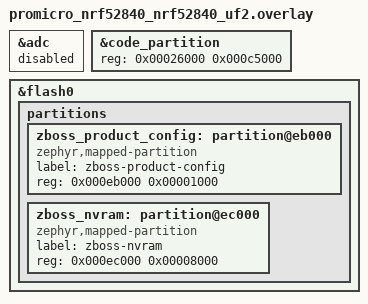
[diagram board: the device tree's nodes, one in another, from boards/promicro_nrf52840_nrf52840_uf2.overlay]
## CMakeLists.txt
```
cmake_minimum_required(VERSION 3.20.0)
set(ZEPHYR_EXTRA_MODULES "C:/ncs/ncs-zigbee")
find_package(Zephyr REQUIRED HINTS $ENV{ZEPHYR_BASE})
project(zigbutton_diag_d2)
target_sources(app PRIVATE src/main.c src/d2_monitor.c)
get_property(diag_libs GLOBAL PROPERTY ZEPHYR_LIBS)
set(diag_replaced 0)
foreach(diag_lib IN LISTS diag_libs)
  get_target_property(diag_sources ${diag_lib} SOURCES)
  if(diag_sources)
    set(diag_new_sources "")
    foreach(diag_source IN LISTS diag_sources)
      if(diag_source MATCHES "(^|/)zb_nrf_platform[.]c$")
        list(APPEND diag_new_sources "${CMAKE_CURRENT_SOURCE_DIR}/src/zb_nrf_platform_d2.c")
        math(EXPR diag_replaced "${diag_replaced} + 1")
      else()
        list(APPEND diag_new_sources "${diag_source}")
      endif()
    endforeach()
    set_property(TARGET ${diag_lib} PROPERTY SOURCES "${diag_new_sources}")
  endif()
endforeach()
if(NOT diag_replaced EQUAL 1)
  message(FATAL_ERROR "D2 must replace exactly one OSIF platform source; found ${diag_replaced}")
endif()
```

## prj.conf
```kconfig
CONFIG_GPIO=y
CONFIG_ADC=n
CONFIG_HEAP_MEM_POOL_SIZE=2048
CONFIG_SYSTEM_WORKQUEUE_STACK_SIZE=2048
CONFIG_RAM_POWER_DOWN_LIBRARY=y
CONFIG_PM_DEVICE=n
CONFIG_WATCHDOG=n
CONFIG_SERIAL=n
CONFIG_CONSOLE=n
CONFIG_UART_CONSOLE=n
CONFIG_LOG=n
CONFIG_SHELL=n
CONFIG_USB_DEVICE_STACK=n
CONFIG_USB_DEVICE_STACK_NEXT=n
CONFIG_DK_LIBRARY=n
CONFIG_DIAG_ZIGBEE=y
CONFIG_ZIGBEE_ADD_ON=y
CONFIG_ZIGBEE_APP_UTILS=y
CONFIG_ZIGBEE_ROLE_END_DEVICE=y
CONFIG_ZIGBEE_CHANNEL_SELECTION_MODE_SINGLE=y
CONFIG_ZIGBEE_CHANNEL=11
```

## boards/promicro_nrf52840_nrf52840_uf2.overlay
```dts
/* Exact original partition map; ADC disabled for BOTH diagnostics. */
&adc { status = "disabled"; };

&code_partition {
    reg = <0x00026000 0x000c5000>;
};


/delete-node/ &storage_partition;


&flash0 {
    partitions {

        zboss_product_config: partition@eb000 {
            compatible = "zephyr,mapped-partition";
            label = "zboss-product-config";
            reg = <0x000eb000 0x00001000>;
        };

        zboss_nvram: partition@ec000 {
            compatible = "zephyr,mapped-partition";
            label = "zboss-nvram";
            reg = <0x000ec000 0x00008000>;
        };
    };
};
```

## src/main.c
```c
#include <zephyr/kernel.h>
#include <zephyr/drivers/gpio.h>
#include <zephyr/sys/atomic.h>
#include <ram_pwrdn.h>
#include "d2_monitor.h"

#define BUTTON_PIN 17
#define DEBOUNCE_MS 35
#define LED_MS 20
static const struct device *gpio0 = DEVICE_DT_GET(DT_NODELABEL(gpio0));
static const struct gpio_dt_spec led = GPIO_DT_SPEC_GET(DT_ALIAS(led0), gpios);
static struct gpio_callback button_cb;
static struct k_work_delayable debounce_work, led_off_work;
static int last_state;
static struct k_work_delayable status_work;
static atomic_t status_request;
static unsigned int status_edges;
static bool status_on;
static void status_handler(struct k_work *work)
{
    ARG_UNUSED(work);
    unsigned int request = atomic_set(&status_request, 0);
    if (request) { status_edges = request * 2; status_on = false; }
    if (!status_edges) { return; }
    status_on = !status_on;
    if (gpio_pin_set_dt(&led, status_on) != 0) { return; }
    status_edges--;
    if (status_edges) {
        k_work_reschedule(&status_work, status_on ? K_MSEC(150) : K_MSEC(350));
    }
}
static void show_status(unsigned int count)
{
    atomic_set(&status_request, count);
    k_work_reschedule(&status_work, K_MSEC(700));
}

/* RAM-only diagnostics; no periodic work, logging or flash writes. */
volatile int diag_init_error;
atomic_t diag_irq_count, diag_gpio_errors, diag_scheduler_errors;

#if defined(CONFIG_DIAG_ZIGBEE)
/* Cluster support is supplied by this add-on libzboss configuration. */
#include <zboss_api.h>
#include <zboss_api_addons.h>
#include <zboss_api_zcl.h>
/* On/Off diagnostic endpoint, device version 0. */
#include <zigbee/zigbee_app_utils.h>
#include <zb_nrf_platform.h>
static zb_zcl_basic_attrs_t basic;
static zb_zcl_identify_attrs_t identify;
volatile uint32_t diag_buffer_errors, diag_not_joined, diag_sleep_signals;
volatile zb_bool_t diag_rx_on_when_idle;
volatile zb_ret_t diag_last_signal_status, diag_last_buffer_result;
ZB_ZCL_DECLARE_BASIC_SERVER_ATTRIB_LIST(basic_attrs, &basic.zcl_version, &basic.power_source);
ZB_ZCL_DECLARE_IDENTIFY_SERVER_ATTRIB_LIST(identify_attrs, &identify.identify_time);
static zb_zcl_cluster_desc_t clusters[] = {
    ZB_ZCL_CLUSTER_DESC(ZB_ZCL_CLUSTER_ID_BASIC, ZB_ZCL_ARRAY_SIZE(basic_attrs, zb_zcl_attr_t), basic_attrs, ZB_ZCL_CLUSTER_SERVER_ROLE, ZB_ZCL_MANUF_CODE_INVALID),
    ZB_ZCL_CLUSTER_DESC(ZB_ZCL_CLUSTER_ID_IDENTIFY, ZB_ZCL_ARRAY_SIZE(identify_attrs, zb_zcl_attr_t), identify_attrs, ZB_ZCL_CLUSTER_SERVER_ROLE, ZB_ZCL_MANUF_CODE_INVALID),
    ZB_ZCL_CLUSTER_DESC(ZB_ZCL_CLUSTER_ID_ON_OFF, 0, NULL, ZB_ZCL_CLUSTER_CLIENT_ROLE, ZB_ZCL_MANUF_CODE_INVALID),
};
ZB_DECLARE_SIMPLE_DESC(2, 1);
ZB_AF_SIMPLE_DESC_TYPE(2, 1) simple_desc = {
    1, ZB_AF_HA_PROFILE_ID, ZB_HA_ON_OFF_SWITCH_DEVICE_ID,
    0, 0, 2, 1,
    { ZB_ZCL_CLUSTER_ID_BASIC, ZB_ZCL_CLUSTER_ID_IDENTIFY, ZB_ZCL_CLUSTER_ID_ON_OFF }
};
ZB_AF_DECLARE_ENDPOINT_DESC(ep, 1, ZB_AF_HA_PROFILE_ID, 0, NULL,
    ZB_ZCL_ARRAY_SIZE(clusters, zb_zcl_cluster_desc_t), clusters,
    (zb_af_simple_desc_1_1_t *)&simple_desc, 0, NULL, 0, NULL);
ZBOSS_DECLARE_DEVICE_CTX_1_EP(device_ctx, ep);

static void send_toggle(zb_bufid_t bufid)
{
    if (!ZB_JOINED()) {
        diag_not_joined++;
        zb_buf_free(bufid);
        return;
    }
    zb_uint16_t destination = 0x0000;
    ZB_ZCL_ON_OFF_SEND_REQ(bufid, destination, ZB_APS_ADDR_MODE_16_ENDP_PRESENT,
        1, 1, ZB_AF_HA_PROFILE_ID, ZB_ZCL_DISABLE_DEFAULT_RESPONSE,
        ZB_ZCL_CMD_ON_OFF_TOGGLE_ID, NULL);
}
static void button_zigbee(zb_uint8_t param, zb_uint16_t unused)
{
    ARG_UNUSED(param);
    ARG_UNUSED(unused);
    show_status(d2_classify(ZB_JOINED()));
    user_input_indicate();
    diag_last_buffer_result = zb_buf_get_out_delayed(send_toggle);
    if (diag_last_buffer_result != RET_OK) {
        diag_buffer_errors++;
    }
}
void zboss_signal_handler(zb_bufid_t bufid)
{
    zb_zdo_app_signal_type_t signal = zb_get_app_signal(bufid, NULL);
    diag_rx_on_when_idle = zb_get_rx_on_when_idle();
    if (signal == ZB_COMMON_SIGNAL_CAN_SLEEP) {
        diag_sleep_signals++;
    }
    diag_last_signal_status = zigbee_default_signal_handler(bufid);
    if (bufid) {
        zb_buf_free(bufid);
    }
}
#endif

static void led_off(struct k_work *work)
{
    ARG_UNUSED(work);
    if (gpio_pin_set_dt(&led, 0) != 0) {
        atomic_inc(&diag_gpio_errors);
    }
}
static void debounce(struct k_work *work)
{
    ARG_UNUSED(work);
    int state = gpio_pin_get(gpio0, BUTTON_PIN);
    if (state < 0) {
        atomic_inc(&diag_gpio_errors);
        return;
    }
    if (state == last_state) {
        return;
    }
    last_state = state;
#if defined(CONFIG_DIAG_ZIGBEE)
    if (ZB_SCHEDULE_APP_CALLBACK2(button_zigbee, 0, 0) != RET_OK) {
        atomic_inc(&diag_scheduler_errors);
    }
#endif
}
static void button_irq(const struct device *dev, struct gpio_callback *cb, uint32_t pins)
{
    ARG_UNUSED(dev);
    ARG_UNUSED(cb);
    ARG_UNUSED(pins);
    atomic_inc(&diag_irq_count);
    if (gpio_pin_set_dt(&led, 1) != 0) {
        atomic_inc(&diag_gpio_errors);
    }
    if (k_work_reschedule(&led_off_work, K_MSEC(LED_MS)) < 0) {
        atomic_inc(&diag_scheduler_errors);
    }
    if (k_work_reschedule(&debounce_work, K_MSEC(DEBOUNCE_MS)) < 0) {
        atomic_inc(&diag_scheduler_errors);
    }
}
static int gpio_init(void)
{
    if (!device_is_ready(gpio0) || !gpio_is_ready_dt(&led)) {
        return -ENODEV;
    }
    int err = gpio_pin_configure_dt(&led, GPIO_OUTPUT_INACTIVE);
    if (err) { return err; }
    err = gpio_pin_configure(gpio0, BUTTON_PIN, GPIO_INPUT | GPIO_PULL_UP);
    if (err) { return err; }
    last_state = gpio_pin_get(gpio0, BUTTON_PIN);
    if (last_state < 0) { return last_state; }
    k_work_init_delayable(&led_off_work, led_off);
    k_work_init_delayable(&debounce_work, debounce);
    gpio_init_callback(&button_cb, button_irq, BIT(BUTTON_PIN));
    err = gpio_add_callback(gpio0, &button_cb);
    if (err) { return err; }
    return gpio_pin_interrupt_configure(gpio0, BUTTON_PIN, GPIO_INT_EDGE_BOTH);
}
int main(void)
{
    k_work_init_delayable(&status_work, status_handler);
    d2_monitor_init();
    diag_init_error = gpio_init();
    if (diag_init_error) { return 0; }
#if defined(CONFIG_DIAG_ZIGBEE)
    basic.zcl_version = ZB_ZCL_VERSION;
    basic.power_source = ZB_ZCL_BASIC_POWER_SOURCE_BATTERY;
    identify.identify_time = ZB_ZCL_IDENTIFY_IDENTIFY_TIME_DEFAULT_VALUE;
    ZB_AF_REGISTER_DEVICE_CTX(&device_ctx);
    zigbee_configure_sleepy_behavior(true);
    diag_rx_on_when_idle = zb_get_rx_on_when_idle();
#endif
    if (IS_ENABLED(CONFIG_RAM_POWER_DOWN_LIBRARY)) { power_down_unused_ram(); }
#if defined(CONFIG_DIAG_ZIGBEE)
    zigbee_enable();
#endif
    /* Block main permanently. Zephyr idle performs architecture CPU sleep. */
    k_sleep(K_FOREVER);
    return 0;
}
```

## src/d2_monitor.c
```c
/* Observation only: same-thread accounting around the original k_poll.
 * Wall time inside k_poll is NOT a measurement of CPU idle or radio-off time.
 * All calls after init run in the ZBOSS thread. No timer and no extra wakeup.
 */
#include <zephyr/kernel.h>
#include "d2_monitor.h"
static int64_t window_start, poll_start;
static uint64_t poll_ticks;
static uint32_t calls;
volatile uint32_t d2_last_poll_percent, d2_last_window_seconds, d2_last_poll_calls;
volatile unsigned int d2_last_code;
void d2_monitor_init(void)
{
    window_start = k_uptime_ticks();
}
void d2_poll_begin(void)
{
    poll_start = k_uptime_ticks();
}
void d2_poll_end(void)
{
    poll_ticks += (uint64_t)(k_uptime_ticks() - poll_start);
    calls++;
}
unsigned int d2_classify(bool joined)
{
    int64_t now = k_uptime_ticks();
    uint64_t elapsed = (uint64_t)(now - window_start);
    d2_last_window_seconds = k_ticks_to_ms_floor64(elapsed) / 1000;
    d2_last_poll_calls = calls;
    d2_last_poll_percent = elapsed ? MIN(100ULL, (poll_ticks * 100ULL) / elapsed) : 0;
    unsigned int code;
    if (!joined) { code = 4; }
    else if (d2_last_window_seconds < 60) { code = 5; }
    else if (d2_last_poll_percent >= 90) { code = 1; }
    else if (d2_last_poll_percent >= 10) { code = 2; }
    else { code = 3; }
    if (d2_last_window_seconds >= 60) {
        window_start = now;
        poll_ticks = 0;
        calls = 0;
    }
    d2_last_code = code;
    return code;
}
```

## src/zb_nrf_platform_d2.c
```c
/*
 * Copyright (c) 2020 Nordic Semiconductor ASA
 *
 * SPDX-License-Identifier: LicenseRef-Nordic-5-Clause
 */

#include <stdlib.h>
#include "d2_monitor.h"
#include <string.h>
#include <zephyr/kernel.h>
#include <zephyr/sys/byteorder.h>
#include <zephyr/sys/reboot.h>
#include <zephyr/logging/log.h>
#include <zephyr/logging/log_ctrl.h>
#include <zephyr/init.h>
#include <ram_pwrdn.h>

#include <hal/nrf_power.h>
#include <hal/nrf_ficr.h>
#if !NRF_POWER_HAS_RESETREAS
#include <hal/nrf_reset.h>
#endif

#ifdef CONFIG_ZIGBEE_SHELL
#include <zigbee/zigbee_shell.h>
#endif
#include <zboss_api.h>
#include "zb_nrf_platform.h"
#include "zb_nrf_crypto.h"

#ifdef CONFIG_ZIGBEE_LIBRARY_NCP_DEV
#include <zb_ncp_nrf_platform.h>
#define SYS_REBOOT_NCP 0x10
#endif /* CONFIG_ZIGBEE_LIBRARY_NCP_DEV */

/* Value that is returned while reading a single byte from the erased flash page .*/
#define FLASH_EMPTY_BYTE 0xFF
/* Broadcast Pan ID value */
#define ZB_BROADCAST_PAN_ID 0xFFFFU
/* The number of bytes to be checked before concluding that the ZBOSS NVRAM is not initialized. */
#define ZB_PAGE_INIT_CHECK_LEN 32

/* EUI64 address configuration */
#if defined(CONFIG_ZIGBEE_UICR_EUI64_ENABLE)
#if defined(CONFIG_SOC_NRF5340_CPUAPP) || defined(CONFIG_SOC_SERIES_NRF54LX)
#define EUI64_ADDR (NRF_UICR->OTP)
#else
#define EUI64_ADDR (NRF_UICR->CUSTOMER)
#endif
#define EUI64_ADDR_HIGH CONFIG_ZIGBEE_UICR_EUI64_REG
#define EUI64_ADDR_LOW  (CONFIG_ZIGBEE_UICR_EUI64_REG + 1)
#else
#define EUI64_ADDR_HIGH 0
#define EUI64_ADDR_LOW  1
#endif /* CONFIG_ZIGBEE_UICR_EUI64_ENABLE */


/**
 * Enumeration representing type of application callback to execute from ZBOSS
 * context.
 */
typedef enum {
	ZB_CALLBACK_TYPE_SINGLE_PARAM,
	ZB_CALLBACK_TYPE_TWO_PARAMS,
	ZB_CALLBACK_TYPE_ALARM_SET,
	ZB_CALLBACK_TYPE_ALARM_CANCEL,
	ZB_GET_OUT_BUF_DELAYED,
	ZB_GET_IN_BUF_DELAYED,
	ZB_GET_OUT_BUF_DELAYED_EXT,
	ZB_GET_IN_BUF_DELAYED_EXT,
} zb_callback_type_t;

/**
 * Type definition of element of the application callback and alarm queue.
 */
typedef struct {
	zb_callback_type_t type;
	zb_callback_t func;
	zb_callback2_t func2;
	zb_uint16_t param;
	zb_uint16_t user_param;
	int64_t alarm_timestamp;
} zb_app_cb_t;


LOG_MODULE_REGISTER(zboss_osif, CONFIG_ZBOSS_OSIF_LOG_LEVEL);

BUILD_ASSERT(CONFIG_ZBOSS_INIT_PRIORITY > CONFIG_ZBOSS_RADIO_INIT_PRIORITY,
	     "ZBOSS init priority must be greater than radio init priority");

/* Signal object to indicate that frame has been received */
static struct k_poll_signal zigbee_sig = K_POLL_SIGNAL_INITIALIZER(zigbee_sig);

/** Global mutex to protect access to the ZBOSS global state.
 *
 * @note Functions for locking/unlocking the mutex are called directly from
 *       ZBOSS core, when the main ZBOSS global variable is accessed.
 */
static K_MUTEX_DEFINE(zigbee_mutex);

/**
 * Message queue, that is used to pass ZBOSS callbacks and alarms from
 * ISR and other threads to ZBOSS main loop context.
 */
K_MSGQ_DEFINE(zb_app_cb_msgq, sizeof(zb_app_cb_t),
	      CONFIG_ZIGBEE_APP_CB_QUEUE_LENGTH, 4);

/**
 * Work queue that will schedule processing of callbacks from the message queue.
 */
static struct k_work zb_app_cb_work;

/**
 * Atomic flag, indicating that the processing callback is still scheduled for
 * execution,
 */
volatile atomic_t zb_app_cb_process_scheduled = ATOMIC_INIT(0);

K_THREAD_STACK_DEFINE(zboss_stack_area, CONFIG_ZBOSS_DEFAULT_THREAD_STACK_SIZE);
static struct k_thread zboss_thread_data;
static k_tid_t zboss_tid;
static bool stack_is_started;

#ifdef CONFIG_ZIGBEE_DEBUG_FUNCTIONS
/**@brief Function for checking if the ZBOSS thread has been created.
 */
bool zigbee_debug_zboss_thread_is_created(void)
{
	if (zboss_tid) {
		return true;
	}
	return false;
}

/**@brief Function for suspending ZBOSS thread.
 */
void zigbee_debug_suspend_zboss_thread(void)
{
	k_thread_suspend(zboss_tid);
}

/**@brief Function for resuming ZBOSS thread.
 */
void zigbee_debug_resume_zboss_thread(void)
{
	k_thread_resume(zboss_tid);
}

/**@brief Function for getting the state of the Zigbee stack thread
 *        processing suspension.
 */
bool zigbee_is_zboss_thread_suspended(void)
{
	if (zboss_tid) {
		if (!(zboss_tid->base.thread_state & _THREAD_SUSPENDED)) {
			return false;
		}
	}
	return true;
}
#endif /* defined(CONFIG_ZIGBEE_DEBUG_FUNCTIONS) */

/**@brief Function for checking if the Zigbee stack has been started.
 *
 * @retval true   Zigbee stack has been started.
 * @retval false  Zigbee stack has not been started yet.
 */
bool zigbee_is_stack_started(void)
{
	return stack_is_started;
}

static void zb_app_cb_process(zb_bufid_t bufid)
{
	zb_ret_t ret_code = RET_OK;
	zb_app_cb_t new_app_cb;

	/* Mark the processing callback as non-scheduled. */
	(void)atomic_set((atomic_t *)&zb_app_cb_process_scheduled, 0);

	/**
	 * From ZBOSS main loop context: process all requests.
	 *
	 * Note: the ZB_SCHEDULE_APP_ALARM is not thread-safe.
	 */
	while (!k_msgq_peek(&zb_app_cb_msgq, &new_app_cb)) {
		switch (new_app_cb.type) {
		case ZB_CALLBACK_TYPE_SINGLE_PARAM:
			ret_code = zb_schedule_app_callback(
					new_app_cb.func,
					(zb_uint8_t)new_app_cb.param);
			break;
		case ZB_CALLBACK_TYPE_TWO_PARAMS:
			ret_code = zb_schedule_app_callback2(
					new_app_cb.func2,
					(zb_uint8_t)new_app_cb.param,
					new_app_cb.user_param);
			break;
		case ZB_CALLBACK_TYPE_ALARM_SET:
		{
			/**
			 * Check if the timeout already passed. If so, use the
			 * lowest value that schedules an alarm, so the user
			 * is still able to cancel the alarm.
			 */
			zb_time_t delay =
				(k_uptime_get() > new_app_cb.alarm_timestamp ?
					1 :
					ZB_MILLISECONDS_TO_BEACON_INTERVAL(
						new_app_cb.alarm_timestamp -
						k_uptime_get())
				);
			ret_code = zb_schedule_app_alarm(
					new_app_cb.func,
					(zb_uint8_t)new_app_cb.param,
					delay);
			break;
		}
		case ZB_CALLBACK_TYPE_ALARM_CANCEL:
			ret_code = zb_schedule_alarm_cancel(
					new_app_cb.func,
					(zb_uint8_t)new_app_cb.param,
					NULL);
			break;
		case ZB_GET_OUT_BUF_DELAYED:
			ret_code = zb_buf_get_out_delayed_func(
				TRACE_CALL(new_app_cb.func));
			break;
		case ZB_GET_IN_BUF_DELAYED:
			ret_code = zb_buf_get_in_delayed_func(
				TRACE_CALL(new_app_cb.func));
			break;
		case ZB_GET_OUT_BUF_DELAYED_EXT:
			ret_code = zb_buf_get_out_delayed_ext_func(
					TRACE_CALL(new_app_cb.func2),
					new_app_cb.user_param,
					new_app_cb.param);
			break;
		case ZB_GET_IN_BUF_DELAYED_EXT:
			ret_code = zb_buf_get_in_delayed_ext_func(
					TRACE_CALL(new_app_cb.func2),
					new_app_cb.user_param,
					new_app_cb.param);
			break;
		default:
			break;
		}

		/* Check for ZBOSS scheduler queue overflow. */
		if (ret_code == RET_OVERFLOW) {
			break;
		}

		/* Flush the element from the message queue. */
		k_msgq_get(&zb_app_cb_msgq, &new_app_cb, K_NO_WAIT);
	}

	/**
	 * In case of overflow error - reschedule the processing callback
	 * to process remaining requests later.
	 */
	if (ret_code == RET_OVERFLOW) {
		k_work_submit(&zb_app_cb_work);
	}
}

static void zb_app_cb_process_schedule(struct k_work *item)
{
	zb_app_cb_t new_app_cb;

	if (k_msgq_peek(&zb_app_cb_msgq, &new_app_cb)) {
		return;
	}

	/* Check if processing callback is already scheduled. */
	if (atomic_set((atomic_t *)&zb_app_cb_process_scheduled, 1) == 1) {
		return;
	}

	/**
	 * From working thread, non-ISR context: schedule processing callback.
	 * Repeat endlessly, because the user was already informed that the
	 * request will be handled.
	 *
	 * Note: the ZB_SCHEDULE_APP_CALLBACK is thread-safe.
	 */
	while (zb_schedule_app_callback(zb_app_cb_process, 0) != RET_OK) {
		k_sleep(K_MSEC(1000));
	}
	zigbee_event_notify(ZIGBEE_EVENT_APP);

	(void)item;
}

int zigbee_init(void)
{
	/* Initialise work queue for processing app callback and alarms. */
	k_work_init(&zb_app_cb_work, zb_app_cb_process_schedule);

#if ZB_TRACE_LEVEL
	/* Set Zigbee stack logging level and traffic dump subsystem. */
	ZB_SET_TRACE_LEVEL(CONFIG_ZBOSS_TRACE_LOG_LEVEL);
	ZB_SET_TRACE_MASK(CONFIG_ZBOSS_TRACE_MASK);
#if CONFIG_ZBOSS_TRAF_DUMP
	ZB_SET_TRAF_DUMP_ON();
#else /* CONFIG_ZBOSS_TRAF_DUMP */
	ZB_SET_TRAF_DUMP_OFF();
#endif /* CONFIG_ZBOSS_TRAF_DUMP */
#endif /* ZB_TRACE_LEVEL */

#ifndef CONFIG_ZB_TEST_MODE_MAC
	/* Initialize Zigbee stack. */
	ZB_INIT("zigbee_thread");

	/* Set device address to the value read from FICR registers. */
	zb_ieee_addr_t ieee_addr;
	zb_osif_get_ieee_eui64(ieee_addr);
	zb_set_long_address(ieee_addr);

	/* Keep or erase NVRAM to save the network parameters
	 * after device reboot or power-off.
	 */
	zb_set_nvram_erase_at_start(ZB_FALSE);

	if (IS_ENABLED(CONFIG_ZIGBEE_TC_REJOIN_ENABLED)) {
		zb_secur_set_tc_rejoin_enabled((zb_bool_t)CONFIG_ZIGBEE_TC_REJOIN_ENABLED);
	}

	/* Don't set zigbee role for NCP device */
#ifndef CONFIG_ZIGBEE_LIBRARY_NCP_DEV

	/* Set channels on which the coordinator will try
	 * to create a new network
	 */
#if defined(CONFIG_ZIGBEE_CHANNEL_SELECTION_MODE_SINGLE)
	zb_uint32_t channel_mask = (1UL << CONFIG_ZIGBEE_CHANNEL);
#elif defined(CONFIG_ZIGBEE_CHANNEL_SELECTION_MODE_MULTI)
	zb_uint32_t channel_mask = CONFIG_ZIGBEE_CHANNEL_MASK;
#else
#error Channel mask undefined!
#endif


#if defined(CONFIG_ZIGBEE_ROLE_COORDINATOR)
	zb_set_network_coordinator_role(channel_mask);
#elif defined(CONFIG_ZIGBEE_ROLE_ROUTER)
	zb_set_network_router_role(channel_mask);

#elif defined(CONFIG_ZIGBEE_ROLE_END_DEVICE)
	zb_set_network_ed_role(channel_mask);
#else
#error Zigbee device role undefined!
#endif

#endif /* CONFIG_ZIGBEE_LIBRARY_NCP_DEV */

#endif /* CONFIG_ZB_TEST_MODE_MAC */

	return 0;
}

SYS_INIT(zigbee_init, POST_KERNEL, CONFIG_ZBOSS_INIT_PRIORITY);

void zigbee_deinit(void)
{
	if (zboss_tid) {
		k_thread_abort(zboss_tid);
		zboss_tid = NULL;
	}

	stack_is_started = false;
	(void)k_work_cancel(&zb_app_cb_work);
	k_msgq_purge(&zb_app_cb_msgq);
	k_poll_signal_reset(&zigbee_sig);
	(void)atomic_clear((atomic_t *)&zb_app_cb_process_scheduled);
}

#if IS_ENABLED(CONFIG_ZIGBEE_LIBRARY_NCP_DEV)
void zb_ncp_app_fw_custom_post_start(void)
{
	stack_is_started = true;
#ifdef CONFIG_ZIGBEE_SHELL
	zb_shell_configure_endpoint();
#endif /* defined(CONFIG_ZIGBEE_SHELL) */
}
#endif

static void zboss_thread(void *arg1, void *arg2, void *arg3)
{
#if !IS_ENABLED(CONFIG_ZIGBEE_LIBRARY_NCP_DEV)
	zb_ret_t zb_err_code;

	zb_err_code = zboss_start_no_autostart();
	__ASSERT(zb_err_code == RET_OK, "Error when starting ZBOSS stack!");

	stack_is_started = true;
#ifdef CONFIG_ZIGBEE_SHELL
	zb_shell_configure_endpoint();
#endif /* defined(CONFIG_ZIGBEE_SHELL) */

	while (1) {
		zboss_main_loop_iteration();
	}

#else /* CONFIG_ZIGBEE_LIBRARY_NCP_DEV */
	/* For NCP mode, the thread implementation (i.e. some initialization part
	 * and main loop) is in the ZBOSS library.
	 */
	zboss_app_main();
#endif
}

zb_bool_t zb_osif_is_inside_isr(void)
{
	return (zb_bool_t)(__get_IPSR() != 0);
}

void zb_osif_enable_all_inter(void)
{
	__ASSERT(zb_osif_is_inside_isr() == 0,
		 "Unable to unlock mutex from interrupt context");
	k_mutex_unlock(&zigbee_mutex);
}

void zb_osif_disable_all_inter(void)
{
	__ASSERT(zb_osif_is_inside_isr() == 0,
		 "Unable to lock mutex from interrupt context");
	k_mutex_lock(&zigbee_mutex, K_FOREVER);
}

zb_ret_t zigbee_schedule_callback(zb_callback_t func, zb_uint8_t param)
{
	if ((zboss_tid) && (k_current_get() == zboss_tid) && (!zb_osif_is_inside_isr())) {
		return zb_schedule_app_callback(func, param);
	}

	zb_app_cb_t new_app_cb = {
		.type = ZB_CALLBACK_TYPE_SINGLE_PARAM,
		.func = func,
		.param = param,
	};

	if (k_msgq_put(&zb_app_cb_msgq, &new_app_cb, K_NO_WAIT)) {
		return RET_OVERFLOW;
	}

	k_work_submit(&zb_app_cb_work);
	return RET_OK;
}

zb_ret_t zigbee_schedule_callback2(zb_callback2_t func,
				   zb_uint8_t param,
				   zb_uint16_t user_param)
{
	if ((zboss_tid) && (k_current_get() == zboss_tid) && (!zb_osif_is_inside_isr())) {
		return zb_schedule_app_callback2(func, param, user_param);
	}

	zb_app_cb_t new_app_cb = {
		.type = ZB_CALLBACK_TYPE_TWO_PARAMS,
		.func2 = func,
		.param = param,
		.user_param = user_param,
	};

	if (k_msgq_put(&zb_app_cb_msgq, &new_app_cb, K_NO_WAIT)) {
		return RET_OVERFLOW;
	}

	k_work_submit(&zb_app_cb_work);
	return RET_OK;
}

zb_ret_t zigbee_schedule_alarm(zb_callback_t func,
			       zb_uint8_t param,
			       zb_time_t run_after)
{
	if ((zboss_tid) && (k_current_get() == zboss_tid) && (!zb_osif_is_inside_isr())) {
		return zb_schedule_app_alarm(func, param, run_after);
	}

	zb_app_cb_t new_app_cb = {
		.type = ZB_CALLBACK_TYPE_ALARM_SET,
		.func = func,
		.param = param,
		.alarm_timestamp = k_uptime_get() +
				   ZB_TIME_BEACON_INTERVAL_TO_MSEC(run_after),
	};

	if (k_msgq_put(&zb_app_cb_msgq, &new_app_cb, K_NO_WAIT)) {
		return RET_OVERFLOW;
	}

	k_work_submit(&zb_app_cb_work);
	return RET_OK;
}

zb_ret_t zigbee_schedule_alarm_cancel(zb_callback_t func, zb_uint8_t param)
{
	if ((zboss_tid) && (k_current_get() == zboss_tid) && (!zb_osif_is_inside_isr())) {
		return zb_schedule_alarm_cancel(func, param, NULL);
	}

	zb_app_cb_t new_app_cb = {
		.type = ZB_CALLBACK_TYPE_ALARM_CANCEL,
		.func = func,
		.param = param,
	};

	if (k_msgq_put(&zb_app_cb_msgq, &new_app_cb, K_NO_WAIT)) {
		return RET_OVERFLOW;
	}

	k_work_submit(&zb_app_cb_work);
	return RET_OK;
}

zb_ret_t zigbee_get_out_buf_delayed(zb_callback_t func)
{
	if ((zboss_tid) && (k_current_get() == zboss_tid) && (!zb_osif_is_inside_isr())) {
		return zb_buf_get_out_delayed_func(func);
	}

	zb_app_cb_t new_app_cb = {
		.type = ZB_GET_OUT_BUF_DELAYED,
		.func = func,
	};

	if (k_msgq_put(&zb_app_cb_msgq, &new_app_cb, K_NO_WAIT)) {
		return RET_OVERFLOW;
	}

	k_work_submit(&zb_app_cb_work);
	return RET_OK;
}

zb_ret_t zigbee_get_in_buf_delayed(zb_callback_t func)
{
	if ((zboss_tid) && (k_current_get() == zboss_tid) && (!zb_osif_is_inside_isr())) {
		return zb_buf_get_in_delayed_func(func);
	}

	zb_app_cb_t new_app_cb = {
		.type = ZB_GET_IN_BUF_DELAYED,
		.func = func,
	};

	if (k_msgq_put(&zb_app_cb_msgq, &new_app_cb, K_NO_WAIT)) {
		return RET_OVERFLOW;
	}

	k_work_submit(&zb_app_cb_work);
	return RET_OK;
}

zb_ret_t zigbee_get_out_buf_delayed_ext(zb_callback2_t func, zb_uint16_t param,
					zb_uint16_t max_size)
{
	if ((zboss_tid) && (k_current_get() == zboss_tid) && (!zb_osif_is_inside_isr())) {
		return zb_buf_get_out_delayed_ext_func(func, param, max_size);
	}

	zb_app_cb_t new_app_cb = {
		.type = ZB_GET_OUT_BUF_DELAYED_EXT,
		.func2 = func,
		.user_param = param,
		.param = max_size,
	};

	if (k_msgq_put(&zb_app_cb_msgq, &new_app_cb, K_NO_WAIT)) {
		return RET_OVERFLOW;
	}

	k_work_submit(&zb_app_cb_work);
	return RET_OK;
}

zb_ret_t zigbee_get_in_buf_delayed_ext(zb_callback2_t func, zb_uint16_t param,
					zb_uint16_t max_size)
{
	if ((zboss_tid) && (k_current_get() == zboss_tid) && (!zb_osif_is_inside_isr())) {
		return zb_buf_get_in_delayed_ext_func(func, param, max_size);
	}

	zb_app_cb_t new_app_cb = {
		.type = ZB_GET_IN_BUF_DELAYED_EXT,
		.func2 = func,
		.user_param = param,
		.param = max_size,
	};

	if (k_msgq_put(&zb_app_cb_msgq, &new_app_cb, K_NO_WAIT)) {
		return RET_OVERFLOW;
	}

	k_work_submit(&zb_app_cb_work);
	return RET_OK;
}

/**@brief SoC general initialization. */
void zb_osif_init(void)
{
	static bool platform_inited;

	if (platform_inited) {
		return;
	}
	platform_inited = true;

#ifdef CONFIG_ZIGBEE_HAVE_SERIAL
	/* Initialise serial trace */
	zb_osif_serial_init();
#endif

	/* Initialise random generator */
	zb_osif_rng_init();

	/* Initialise AES ECB */
	zb_osif_aes_init();

#ifdef ZB_USE_SLEEP
	/* Initialise power consumption routines */
	zb_osif_sleep_init();
#endif /*ZB_USE_SLEEP*/
}

void zb_osif_abort(void)
{
	/* Log ZBOSS error message and flush logs. */
	LOG_ERR("ZBOSS fatal error occurred");
	LOG_PANIC();

#ifdef CONFIG_ZIGBEE_HAVE_SERIAL
	/* Flush ZBOSS trace logs. */
	ZB_OSIF_SERIAL_FLUSH();
#endif

	/* By default reset device or halt if so configured. */
	if (IS_ENABLED(CONFIG_ZBOSS_RESET_ON_ASSERT)) {
		zb_reset(0);
	}
	if (IS_ENABLED(CONFIG_ZBOSS_HALT_ON_ASSERT)) {
		k_fatal_halt(K_ERR_KERNEL_PANIC);
	}
}

uint32_t zigbee_pibcache_pan_id_clear(void)
{
	/* For consistency with zb_nwk_nib_init(), the 0xFFFFU is used,
	 * i.e. ZB_BROADCAST_PAN_ID.
	 */
	ZB_PIBCACHE_PAN_ID() = ZB_BROADCAST_PAN_ID;
	return ZB_BROADCAST_PAN_ID;
}

void zb_reset(zb_uint8_t param)
{
	uint8_t reas = (uint8_t)SYS_REBOOT_COLD;

	ZVUNUSED(param);

#ifdef CONFIG_ZIGBEE_LIBRARY_NCP_DEV
	reas = (uint8_t)SYS_REBOOT_NCP;
#endif /* CONFIG_ZIGBEE_LIBRARY_NCP_DEV */

	nrf_power_gpregret_set(NRF_POWER, 0, reas);

	/* Power on unused sections of RAM to allow MCUboot to use it. */
	if (IS_ENABLED(CONFIG_RAM_POWER_DOWN_LIBRARY)) {
		power_up_unused_ram();
	}

	sys_reboot(reas);
}

void zb_osif_busy_loop_delay(zb_uint32_t count)
{
	k_busy_wait(count);
}

__weak zb_uint32_t zb_get_utc_time(void)
{
	LOG_ERR("Unable to obtain UTC time. "
		"Please implement %s in your application to provide the current UTC time.",
		__func__);
	return ZB_TIME_BEACON_INTERVAL_TO_MSEC(ZB_TIMER_GET()) / 1000;
}

void zb_osif_get_ieee_eui64(zb_ieee_addr_t ieee_eui64)
{
	uint64_t addr;

#if defined(CONFIG_ZIGBEE_UICR_EUI64_ENABLE)
	addr = (uint64_t)EUI64_ADDR[EUI64_ADDR_HIGH] << 32 | EUI64_ADDR[EUI64_ADDR_LOW];
#else
	uint32_t deviceid[2];

	deviceid[0] = nrf_ficr_deviceid_get(NRF_FICR, 0);
	deviceid[1] = nrf_ficr_deviceid_get(NRF_FICR, 1);

	addr = ((uint64_t)deviceid[EUI64_ADDR_HIGH] << 32 | deviceid[EUI64_ADDR_LOW]) &
	       0x000000FFFFFFFFFFULL;
	addr = (addr << 24) | ((CONFIG_ZIGBEE_VENDOR_OUI & 0xFFU) << 16) |
	       (((CONFIG_ZIGBEE_VENDOR_OUI >> 8) & 0xFFU) << 8) |
	       (CONFIG_ZIGBEE_VENDOR_OUI >> 16);
#endif

	sys_memcpy_swap(ieee_eui64, &addr, sizeof(zb_ieee_addr_t));
}

void zigbee_event_notify(zigbee_event_t event)
{
	k_poll_signal_raise(&zigbee_sig, event);
}

uint32_t zigbee_event_poll(uint32_t timeout_us)
{
	/* Configure event/signals to wait for in zigbee_event_poll function. */
	static struct k_poll_event wait_events[] = {
		K_POLL_EVENT_INITIALIZER(K_POLL_TYPE_SIGNAL,
					 K_POLL_MODE_NOTIFY_ONLY,
					 &zigbee_sig),
	};

	unsigned int signaled = 0;
	int result;
	/* Store timestamp of event polling start. */
	int64_t timestamp_poll_start = k_uptime_ticks();

	d2_poll_begin();
	k_poll(wait_events, 1, K_USEC(timeout_us));
	d2_poll_end();

	k_poll_signal_check(&zigbee_sig, &signaled, &result);
	if (signaled) {
		k_poll_signal_reset(&zigbee_sig);

		LOG_DBG("Received new Zigbee event: 0x%02x", result);
	}

	return k_ticks_to_us_floor32(k_uptime_ticks() - timestamp_poll_start);
}

void zigbee_enable(void)
{
#if IS_ENABLED(CONFIG_ZIGBEE_PRO_CORE_BEHAVIOR_R22)
	zboss_use_r22_behavior();
#endif

	zboss_tid = k_thread_create(&zboss_thread_data,
				    zboss_stack_area,
				    K_THREAD_STACK_SIZEOF(zboss_stack_area),
				    zboss_thread,
				    NULL, NULL, NULL,
				    CONFIG_ZBOSS_DEFAULT_THREAD_PRIORITY,
				    0, K_NO_WAIT);
	k_thread_name_set(&zboss_thread_data, "zboss");
}

/**
 * @brief Get the reason that triggered the last reset
 *
 * @return @ref reset_source
 * */
zb_uint8_t zb_get_reset_source(void)
{
	uint32_t reas;
	uint8_t zb_reason;
#ifdef CONFIG_ZIGBEE_LIBRARY_NCP_DEV
	static uint8_t zephyr_reset_type = 0xFF;

	/* Read the value at the first API call, then use data from RAM. */
	if (zephyr_reset_type == 0xFF) {
		zephyr_reset_type = nrf_power_gpregret_get(NRF_POWER, 0);
	}
#endif /* CONFIG_ZIGBEE_LIBRARY_NCP_DEV */

#if NRF_POWER_HAS_RESETREAS

	reas = nrf_power_resetreas_get(NRF_POWER);
	nrf_power_resetreas_clear(NRF_POWER, reas);
	if (reas & NRF_POWER_RESETREAS_RESETPIN_MASK) {
		zb_reason = ZB_RESET_SRC_RESET_PIN;
	} else if (reas & NRF_POWER_RESETREAS_SREQ_MASK) {
		zb_reason = ZB_RESET_SRC_SW_RESET;
	} else if (reas) {
		zb_reason = ZB_RESET_SRC_OTHER;
	} else {
		zb_reason = ZB_RESET_SRC_POWER_ON;
	}

#else

	reas = nrf_reset_resetreas_get(NRF_RESET);
	nrf_reset_resetreas_clear(NRF_RESET, reas);
	if (reas & NRF_RESET_RESETREAS_RESETPIN_MASK) {
		zb_reason = ZB_RESET_SRC_RESET_PIN;
	} else if (reas & NRF_RESET_RESETREAS_SREQ_MASK) {
		zb_reason = ZB_RESET_SRC_SW_RESET;
	} else if (reas) {
		zb_reason = ZB_RESET_SRC_OTHER;
	} else {
		zb_reason = ZB_RESET_SRC_POWER_ON;
	}

#endif

#ifdef CONFIG_ZIGBEE_LIBRARY_NCP_DEV
	if ((zb_reason == ZB_RESET_SRC_SW_RESET) &&
	    (zephyr_reset_type != SYS_REBOOT_NCP)) {
		zb_reason = ZB_RESET_SRC_OTHER;
	}

	/* The NCP reset type is used only by this API call.
	 * Reset the value inside the register, so after the next, external
	 * SW reset, the value will not trigger NCP logic.
	 */
	if (zephyr_reset_type == SYS_REBOOT_NCP) {
		nrf_power_gpregret_set(NRF_POWER, 0, (uint8_t)SYS_REBOOT_COLD);
	}
#endif /* CONFIG_ZIGBEE_LIBRARY_NCP_DEV */

	return zb_reason;
}

zb_bool_t zigbee_is_nvram_initialised(void)
{
	zb_uint8_t buf[ZB_PAGE_INIT_CHECK_LEN] = {0};
	zb_uint8_t i;
	zb_ret_t ret_code;

	ret_code = zb_osif_nvram_read(0, 0, buf, sizeof(buf));
	if (ret_code != RET_OK) {
		return ZB_FALSE;
	}

	for (i = 0; i < sizeof(buf); i++) {
		if (buf[i] != FLASH_EMPTY_BYTE) {
			return ZB_TRUE;
		}
	}

	return ZB_FALSE;
}

ZB_WEAK_PRE zb_uint32_t ZB_WEAK zb_osif_get_fw_version(void)
{
	return 0x01;
}

ZB_WEAK_PRE zb_uint32_t ZB_WEAK zb_osif_get_ncp_protocol_version(void)
{
#ifdef ZB_NCP_PROTOCOL_VERSION
	return ZB_NCP_PROTOCOL_VERSION;
#else /* ZB_NCP_PROTOCOL_VERSION */
	return 0x01;
#endif /* ZB_NCP_PROTOCOL_VERSION */
}

ZB_WEAK_PRE zb_ret_t ZB_WEAK zb_osif_bootloader_run_after_reboot(void)
{
	return RET_OK;
}

ZB_WEAK_PRE void ZB_WEAK zb_osif_bootloader_report_successful_loading(void)
{
}
```
